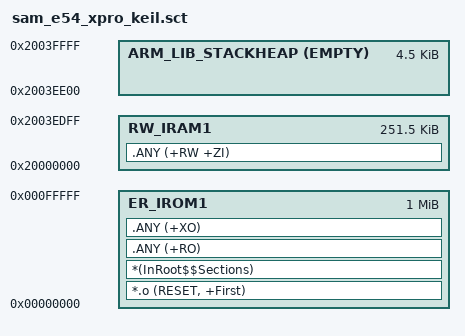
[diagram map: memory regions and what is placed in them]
; ***************************************************************
; *** Scatter-Loading Description File generated by Harmony 3 ***
; ***************************************************************

LR_IROM1 0x00000000 0x100000  {    ; load region size_region
   ER_IROM1 0x00000000 0x100000  {  ; load address = execution address
    *.o (RESET, +First)
    *(InRoot$$Sections)
    .ANY (+RO)
    .ANY (+XO)
   }
   RW_IRAM1 0x20000000 0x40000 - 0x1200  ; Entire RAM minus the stack and heap block
   {
     .ANY (+RW +ZI)
   }

   ARM_LIB_STACKHEAP 0x20000000 + 0x40000 - 0x1200 ALIGN 8 EMPTY  0x1200 ; Stack heap block
   {

   }

}
